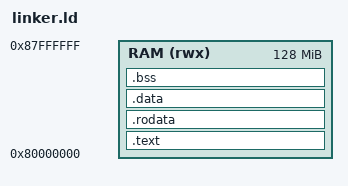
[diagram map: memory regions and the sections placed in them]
/*
 * RISC-V Bare-Metal Linker Script
 * For QEMU virt machine
 */

OUTPUT_ARCH("riscv")
ENTRY(_start)

MEMORY
{
    RAM (rwx) : ORIGIN = 0x80000000, LENGTH = 128M
}

SECTIONS
{
    .text : {
        *(.text.start)
        *(.text*)
    } > RAM

    .rodata : {
        *(.rodata*)
    } > RAM

    .data : {
        *(.data*)
    } > RAM

    .bss : {
        __bss_start = .;
        *(.bss*)
        *(COMMON)
        __bss_end = .;
    } > RAM

    /* Stack grows down from end of RAM */
    . = ORIGIN(RAM) + LENGTH(RAM);
    _stack_top = .;
}
